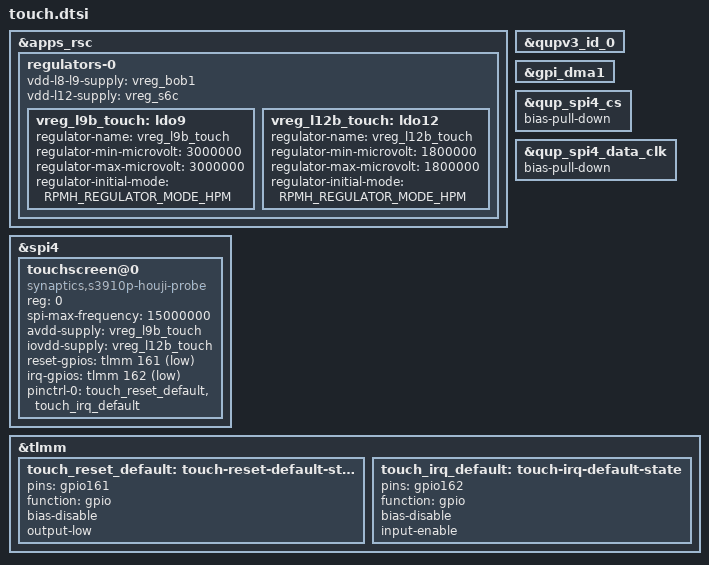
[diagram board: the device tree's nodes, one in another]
#include <dt-bindings/gpio/gpio.h>
#include <dt-bindings/regulator/qcom,rpmh-regulator.h>
/* Synaptics transport for the stock touch processing core. */
&apps_rsc {
	regulators-0 {
		vdd-l8-l9-supply = <&vreg_bob1>;
		vdd-l12-supply = <&vreg_s6c>;
		vreg_l9b_touch: ldo9 {
			regulator-name = "vreg_l9b_touch";
			regulator-min-microvolt = <3000000>;
			regulator-max-microvolt = <3000000>;
			regulator-initial-mode = <RPMH_REGULATOR_MODE_HPM>;
		};
		vreg_l12b_touch: ldo12 {
			regulator-name = "vreg_l12b_touch";
			regulator-min-microvolt = <1800000>;
			regulator-max-microvolt = <1800000>;
			regulator-initial-mode = <RPMH_REGULATOR_MODE_HPM>;
		};
	};
};
&qupv3_id_0 { status = "okay"; };
&gpi_dma1 { status = "okay"; };
&spi4 {
	#address-cells = <1>;
	#size-cells = <0>;
	status = "okay";
	touchscreen@0 {
		compatible = "synaptics,s3910p-houji-probe";
		reg = <0>;
		spi-max-frequency = <15000000>;
		avdd-supply = <&vreg_l9b_touch>;
		iovdd-supply = <&vreg_l12b_touch>;
		reset-gpios = <&tlmm 161 GPIO_ACTIVE_LOW>;
		irq-gpios = <&tlmm 162 GPIO_ACTIVE_LOW>;
		pinctrl-names = "default";
		pinctrl-0 = <&touch_reset_default &touch_irq_default>;
	};
};
&qup_spi4_cs { bias-pull-down; /delete-property/ bias-disable; };
&qup_spi4_data_clk { bias-pull-down; /delete-property/ bias-disable; };
&tlmm {
	touch_reset_default: touch-reset-default-state {
		pins = "gpio161";
		function = "gpio";
		bias-disable;
		output-low;
	};
	touch_irq_default: touch-irq-default-state {
		pins = "gpio162";
		function = "gpio";
		bias-disable;
		input-enable;
	};
};
